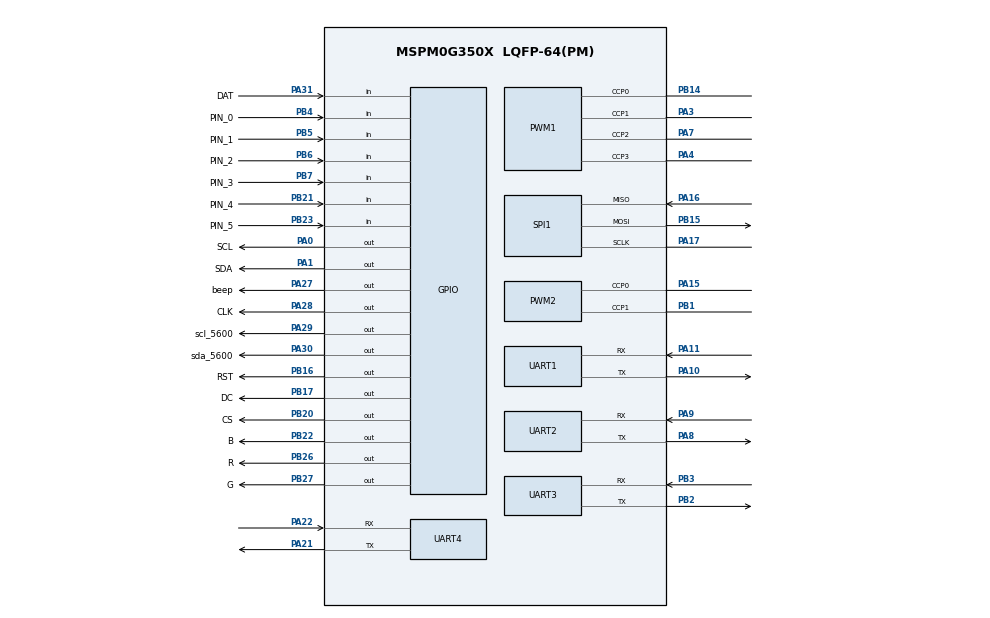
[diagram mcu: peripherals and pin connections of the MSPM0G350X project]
/**
 * @cliArgs --device "MSPM0G350X" --package "LQFP-64(PM)" --part "Default" --product "mspm0_sdk@1.30.00.03"
 * @versions {"tool":"1.20.0+3587"}
 */

/**
 * Import the modules used in this configuration.
 */
const GPIO    = scripting.addModule("/ti/driverlib/GPIO", {}, false);
const GPIO1   = GPIO.addInstance();
const GPIO2   = GPIO.addInstance();
const GPIO3   = GPIO.addInstance();
const GPIO4   = GPIO.addInstance();
const GPIO5   = GPIO.addInstance();
const GPIO6   = GPIO.addInstance();
const GPIO7   = GPIO.addInstance();
const GPIO8   = GPIO.addInstance();
const PWM     = scripting.addModule("/ti/driverlib/PWM", {}, false);
const PWM1    = PWM.addInstance();
const PWM2    = PWM.addInstance();
const SPI     = scripting.addModule("/ti/driverlib/SPI", {}, false);
const SPI1    = SPI.addInstance();
const SYSCTL  = scripting.addModule("/ti/driverlib/SYSCTL");
const SYSTICK = scripting.addModule("/ti/driverlib/SYSTICK");
const TIMER   = scripting.addModule("/ti/driverlib/TIMER", {}, false);
const TIMER1  = TIMER.addInstance();
const UART    = scripting.addModule("/ti/driverlib/UART", {}, false);
const UART1   = UART.addInstance();
const UART2   = UART.addInstance();
const UART3   = UART.addInstance();
const UART4   = UART.addInstance();

/**
 * Write custom configuration values to the imported modules.
 */
const gate7  = system.clockTree["MFCLKGATE"];
gate7.enable = true;

GPIO1.$name                         = "Encoder";
GPIO1.port                          = "PORTB";
GPIO1.associatedPins.create(4);
GPIO1.associatedPins[0].$name       = "PIN_0";
GPIO1.associatedPins[0].direction   = "INPUT";
GPIO1.associatedPins[0].interruptEn = true;
GPIO1.associatedPins[0].polarity    = "RISE";
GPIO1.associatedPins[0].assignedPin = "4";
GPIO1.associatedPins[0].pin.$assign = "PB4";
GPIO1.associatedPins[1].$name       = "PIN_1";
GPIO1.associatedPins[1].direction   = "INPUT";
GPIO1.associatedPins[1].polarity    = "RISE";
GPIO1.associatedPins[1].interruptEn = true;
GPIO1.associatedPins[1].pin.$assign = "PB5";
GPIO1.associatedPins[2].$name       = "PIN_2";
GPIO1.associatedPins[2].direction   = "INPUT";
GPIO1.associatedPins[2].interruptEn = true;
GPIO1.associatedPins[2].polarity    = "RISE";
GPIO1.associatedPins[2].pin.$assign = "PB6";
GPIO1.associatedPins[3].$name       = "PIN_3";
GPIO1.associatedPins[3].direction   = "INPUT";
GPIO1.associatedPins[3].interruptEn = true;
GPIO1.associatedPins[3].polarity    = "RISE";
GPIO1.associatedPins[3].pin.$assign = "PB7";

const Board = scripting.addModule("/ti/driverlib/Board", {}, false);

GPIO2.$name                              = "key";
GPIO2.associatedPins.create(2);
GPIO2.associatedPins[0].$name            = "PIN_4";
GPIO2.associatedPins[0].direction        = "INPUT";
GPIO2.associatedPins[0].internalResistor = "PULL_UP";
GPIO2.associatedPins[0].pin.$assign      = "PB21";
GPIO2.associatedPins[1].$name            = "PIN_5";
GPIO2.associatedPins[1].direction        = "INPUT";
GPIO2.associatedPins[1].internalResistor = "PULL_UP";
GPIO2.associatedPins[1].pin.$assign      = "PB23";

GPIO3.$name                         = "GPIO";
GPIO3.associatedPins.create(2);
GPIO3.associatedPins[0].$name       = "SCL";
GPIO3.associatedPins[0].ioStructure = "OD";
GPIO3.associatedPins[0].pin.$assign = "PA0";
GPIO3.associatedPins[1].$name       = "SDA";
GPIO3.associatedPins[1].ioStructure = "OD";
GPIO3.associatedPins[1].pin.$assign = "PA1";

GPIO4.$name                          = "GrayScale";
GPIO4.associatedPins.create(2);
GPIO4.associatedPins[0].$name        = "CLK";
GPIO4.associatedPins[0].initialValue = "SET";
GPIO4.associatedPins[0].assignedPin  = "28";
GPIO4.associatedPins[0].pin.$assign  = "PA28";
GPIO4.associatedPins[1].$name        = "DAT";
GPIO4.associatedPins[1].direction    = "INPUT";
GPIO4.associatedPins[1].assignedPin  = "31";
GPIO4.associatedPins[1].pin.$assign  = "PA31";

GPIO5.$name                         = "RGB";
GPIO5.associatedPins.create(3);
GPIO5.associatedPins[0].$name       = "R";
GPIO5.associatedPins[0].pin.$assign = "PB26";
GPIO5.associatedPins[1].$name       = "G";
GPIO5.associatedPins[1].pin.$assign = "PB27";
GPIO5.associatedPins[2].$name       = "B";
GPIO5.associatedPins[2].pin.$assign = "PB22";

GPIO6.$name                         = "AS5600";
GPIO6.associatedPins.create(2);
GPIO6.associatedPins[0].$name       = "scl_5600";
GPIO6.associatedPins[0].pin.$assign = "PA29";
GPIO6.associatedPins[1].$name       = "sda_5600";
GPIO6.associatedPins[1].pin.$assign = "PA30";

GPIO7.$name                         = "BEEP";
GPIO7.associatedPins[0].$name       = "beep";
GPIO7.associatedPins[0].pin.$assign = "PA27";

GPIO8.$name                         = "PORTB";
GPIO8.associatedPins.create(3);
GPIO8.associatedPins[0].$name       = "RST";
GPIO8.associatedPins[0].pin.$assign = "PB16";
GPIO8.associatedPins[1].$name       = "DC";
GPIO8.associatedPins[1].pin.$assign = "PB17";
GPIO8.associatedPins[2].$name       = "CS";
GPIO8.associatedPins[2].pin.$assign = "PB20";

PWM1.$name                              = "PWM_Motor";
PWM1.timerCount                         = 3200;
PWM1.ccIndex                            = [0,1,2,3];
PWM1.timerStartTimer                    = true;
PWM1.peripheral.$assign                 = "TIMA0";
PWM1.peripheral.ccp0Pin.$assign         = "PB14";
PWM1.peripheral.ccp1Pin.$assign         = "PA3";
PWM1.peripheral.ccp2Pin.$assign         = "PA7";
PWM1.peripheral.ccp3Pin.$assign         = "PA4";
PWM1.PWM_CHANNEL_0.$name                = "ti_driverlib_pwm_PWMTimerCC0";
PWM1.PWM_CHANNEL_1.$name                = "ti_driverlib_pwm_PWMTimerCC1";
PWM1.ccp0PinConfig.direction            = scripting.forceWrite("OUTPUT");
PWM1.ccp0PinConfig.hideOutputInversion  = scripting.forceWrite(false);
PWM1.ccp0PinConfig.onlyInternalResistor = scripting.forceWrite(false);
PWM1.ccp0PinConfig.passedPeripheralType = scripting.forceWrite("Digital");
PWM1.ccp0PinConfig.$name                = "ti_driverlib_gpio_GPIOPinGeneric5";
PWM1.ccp1PinConfig.direction            = scripting.forceWrite("OUTPUT");
PWM1.ccp1PinConfig.hideOutputInversion  = scripting.forceWrite(false);
PWM1.ccp1PinConfig.onlyInternalResistor = scripting.forceWrite(false);
PWM1.ccp1PinConfig.passedPeripheralType = scripting.forceWrite("Digital");
PWM1.ccp1PinConfig.$name                = "ti_driverlib_gpio_GPIOPinGeneric6";
PWM1.PWM_CHANNEL_2.$name                = "ti_driverlib_pwm_PWMTimerCC3";
PWM1.PWM_CHANNEL_3.$name                = "ti_driverlib_pwm_PWMTimerCC2";
PWM1.ccp2PinConfig.$name                = "ti_driverlib_gpio_GPIOPinGeneric8";
PWM1.ccp3PinConfig.$name                = "ti_driverlib_gpio_GPIOPinGeneric7";

PWM2.$name                              = "Servo";
PWM2.clockDivider                       = 8;
PWM2.timerStartTimer                    = true;
PWM2.timerCount                         = 20000;
PWM2.clockPrescale                      = 4;
PWM2.peripheral.$assign                 = "TIMA1";
PWM2.peripheral.ccp0Pin.$assign         = "PA15";
PWM2.peripheral.ccp1Pin.$assign         = "PB1";
PWM2.PWM_CHANNEL_0.$name                = "ti_driverlib_pwm_PWMTimerCC4";
PWM2.PWM_CHANNEL_0.invert               = true;
PWM2.PWM_CHANNEL_1.$name                = "ti_driverlib_pwm_PWMTimerCC5";
PWM2.PWM_CHANNEL_1.invert               = true;
PWM2.ccp0PinConfig.direction            = scripting.forceWrite("OUTPUT");
PWM2.ccp0PinConfig.hideOutputInversion  = scripting.forceWrite(false);
PWM2.ccp0PinConfig.onlyInternalResistor = scripting.forceWrite(false);
PWM2.ccp0PinConfig.passedPeripheralType = scripting.forceWrite("Digital");
PWM2.ccp0PinConfig.$name                = "ti_driverlib_gpio_GPIOPinGeneric9";
PWM2.ccp1PinConfig.direction            = scripting.forceWrite("OUTPUT");
PWM2.ccp1PinConfig.hideOutputInversion  = scripting.forceWrite(false);
PWM2.ccp1PinConfig.onlyInternalResistor = scripting.forceWrite(false);
PWM2.ccp1PinConfig.passedPeripheralType = scripting.forceWrite("Digital");
PWM2.ccp1PinConfig.$name                = "ti_driverlib_gpio_GPIOPinGeneric10";

SPI1.$name                      = "SPI_0";
SPI1.targetBitRate              = 1000000;
SPI1.frameFormat                = "MOTO3";
SPI1.polarity                   = "1";
SPI1.peripheral.$assign         = "SPI1";
SPI1.peripheral.sclkPin.$assign = "PA17";
SPI1.peripheral.mosiPin.$assign = "PB15";
SPI1.peripheral.misoPin.$assign = "PA16";
SPI1.sclkPinConfig.$name        = "ti_driverlib_gpio_GPIOPinGeneric2";
SPI1.mosiPinConfig.$name        = "ti_driverlib_gpio_GPIOPinGeneric3";
SPI1.misoPinConfig.$name        = "ti_driverlib_gpio_GPIOPinGeneric4";

SYSCTL.forceDefaultClkConfig = true;
SYSCTL.clockTreeEn           = true;

SYSTICK.periodEnable      = true;
SYSTICK.systickEnable     = true;
SYSTICK.interruptPriority = "0";
SYSTICK.period            = 32;

TIMER1.$name            = "TIMER_0";
TIMER1.timerClkDiv      = 8;
TIMER1.timerClkPrescale = 100;
TIMER1.timerMode        = "PERIODIC";
TIMER1.timerStartTimer  = true;
TIMER1.interrupts       = ["ZERO"];
TIMER1.timerPeriod      = "1ms";

UART1.$name                    = "UART_0";
UART1.uartClkSrc               = "MFCLK";
UART1.enabledInterrupts        = ["RX"];
UART1.targetBaudRate           = 115200;
UART1.peripheral.$assign       = "UART0";
UART1.peripheral.rxPin.$assign = "PA11";
UART1.peripheral.txPin.$assign = "PA10";
UART1.txPinConfig.$name        = "ti_driverlib_gpio_GPIOPinGeneric0";
UART1.rxPinConfig.$name        = "ti_driverlib_gpio_GPIOPinGeneric1";

UART2.$name                    = "UART_1";
UART2.uartClkSrc               = "MFCLK";
UART2.targetBaudRate           = 115200;
UART2.enabledInterrupts        = ["RX"];
UART2.peripheral.$assign       = "UART1";
UART2.peripheral.rxPin.$assign = "PA9";
UART2.peripheral.txPin.$assign = "PA8";
UART2.txPinConfig.$name        = "ti_driverlib_gpio_GPIOPinGeneric13";
UART2.rxPinConfig.$name        = "ti_driverlib_gpio_GPIOPinGeneric14";

UART3.$name                            = "UART_3";
UART3.uartClkSrc                       = "MFCLK";
UART3.targetBaudRate                   = 115200;
UART3.enabledInterrupts                = ["RX"];
UART3.peripheral.$assign               = "UART3";
UART3.peripheral.rxPin.$assign         = "PB3";
UART3.peripheral.txPin.$assign         = "PB2";
UART3.txPinConfig.direction            = scripting.forceWrite("OUTPUT");
UART3.txPinConfig.hideOutputInversion  = scripting.forceWrite(false);
UART3.txPinConfig.onlyInternalResistor = scripting.forceWrite(false);
UART3.txPinConfig.passedPeripheralType = scripting.forceWrite("Digital");
UART3.txPinConfig.$name                = "ti_driverlib_gpio_GPIOPinGeneric15";
UART3.rxPinConfig.hideOutputInversion  = scripting.forceWrite(false);
UART3.rxPinConfig.onlyInternalResistor = scripting.forceWrite(false);
UART3.rxPinConfig.passedPeripheralType = scripting.forceWrite("Digital");
UART3.rxPinConfig.$name                = "ti_driverlib_gpio_GPIOPinGeneric16";

UART4.$name                            = "UART_2";
UART4.uartClkSrc                       = "MFCLK";
UART4.targetBaudRate                   = 115200;
UART4.enabledInterrupts                = ["RX"];
UART4.peripheral.$assign               = "UART2";
UART4.peripheral.rxPin.$assign         = "PA22";
UART4.peripheral.txPin.$assign         = "PA21";
UART4.txPinConfig.direction            = scripting.forceWrite("OUTPUT");
UART4.txPinConfig.hideOutputInversion  = scripting.forceWrite(false);
UART4.txPinConfig.onlyInternalResistor = scripting.forceWrite(false);
UART4.txPinConfig.passedPeripheralType = scripting.forceWrite("Digital");
UART4.txPinConfig.$name                = "ti_driverlib_gpio_GPIOPinGeneric11";
UART4.rxPinConfig.hideOutputInversion  = scripting.forceWrite(false);
UART4.rxPinConfig.onlyInternalResistor = scripting.forceWrite(false);
UART4.rxPinConfig.passedPeripheralType = scripting.forceWrite("Digital");
UART4.rxPinConfig.$name                = "ti_driverlib_gpio_GPIOPinGeneric12";

/**
 * Pinmux solution for unlocked pins/peripherals. This ensures that minor changes to the automatic solver in a future
 * version of the tool will not impact the pinmux you originally saw.  These lines can be completely deleted in order to
 * re-solve from scratch.
 */
Board.peripheral.$suggestSolution          = "DEBUGSS";
Board.peripheral.swclkPin.$suggestSolution = "PA20";
Board.peripheral.swdioPin.$suggestSolution = "PA19";
TIMER1.peripheral.$suggestSolution         = "TIMG0";
